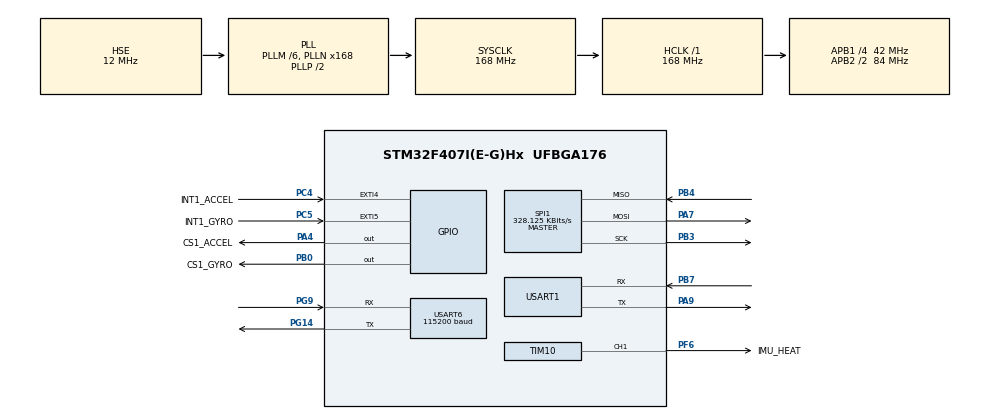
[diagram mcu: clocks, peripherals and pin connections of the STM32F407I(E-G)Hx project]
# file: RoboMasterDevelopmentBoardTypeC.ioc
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Dma.Request0=USART1_TX
Dma.USART1_TX.0.Direction=DMA_MEMORY_TO_PERIPH
Dma.USART1_TX.0.FIFOMode=DMA_FIFOMODE_DISABLE
Dma.USART1_TX.0.Instance=DMA2_Stream7
Dma.USART1_TX.0.MemDataAlignment=DMA_MDATAALIGN_BYTE
Dma.USART1_TX.0.MemInc=DMA_MINC_ENABLE
Dma.USART1_TX.0.Mode=DMA_NORMAL
Dma.USART1_TX.0.PeriphDataAlignment=DMA_PDATAALIGN_BYTE
Dma.USART1_TX.0.PeriphInc=DMA_PINC_DISABLE
Dma.USART1_TX.0.Priority=DMA_PRIORITY_MEDIUM
Mcu.Family=STM32F4
Mcu.Name=STM32F407I(E-G)Hx
Mcu.Package=UFBGA176
NVIC.DMA2_Stream7_IRQn=true\:6\:0\:true\:false\:true\:false\:true\:true
NVIC.PriorityGroup=NVIC_PRIORITYGROUP_4
NVIC.TIM5_IRQn=true\:0\:0\:false\:false\:false\:true\:false\:true
NVIC.TIM7_IRQn=true\:0\:0\:true\:false\:true\:false\:true\:true
NVIC.TimeBase=TIM7_IRQn
NVIC.TimeBaseIP=TIM7
NVIC.USART1_IRQn=true\:6\:0\:true\:false\:true\:true\:true\:true
PA13.Mode=Serial_Wire
PA13.Signal=SYS_JTMS-SWDIO
PA14.Mode=Serial_Wire
PA14.Signal=SYS_JTCK-SWCLK
PA4.GPIO_Label=CS1_ACCEL
PA4.GPIO_ModeDefaultOutputPP=GPIO_MODE_OUTPUT_PP
PA4.GPIO_PuPd=GPIO_PULLUP
PA4.GPIO_Speed=GPIO_SPEED_FREQ_HIGH
PA4.PinState=GPIO_PIN_SET
PA4.Signal=GPIO_Output
PA7.Mode=Full_Duplex_Master
PA7.Signal=SPI1_MOSI
PA9.Mode=Asynchronous
PA9.Signal=USART1_TX
PB0.GPIO_Label=CS1_GYRO
PB0.GPIO_PuPd=GPIO_PULLUP
PB0.GPIO_Speed=GPIO_SPEED_FREQ_HIGH
PB0.PinState=GPIO_PIN_SET
PB0.Signal=GPIO_Output
PB3.Mode=Full_Duplex_Master
PB3.Signal=SPI1_SCK
PB4.Mode=Full_Duplex_Master
PB4.Signal=SPI1_MISO
PB7.Mode=Asynchronous
PB7.Signal=USART1_RX
PC4.GPIO_Label=INT1_ACCEL
PC4.GPIO_ModeDefaultEXTI=GPIO_MODE_IT_FALLING
PC4.GPIO_PuPd=GPIO_PULLUP
PC4.Signal=GPXTI4
PC5.GPIO_Label=INT1_GYRO
PC5.GPIO_ModeDefaultEXTI=GPIO_MODE_IT_FALLING
PC5.GPIO_PuPd=GPIO_PULLUP
PC5.Signal=GPXTI5
PF6.GPIO_Label=IMU_HEAT
PF6.GPIO_PuPd=GPIO_PULLUP
PF6.GPIO_Speed=GPIO_SPEED_FREQ_HIGH
PF6.Signal=S_TIM10_CH1
PG14.Mode=Asynchronous
PG14.Signal=USART6_TX
PG9.Mode=Asynchronous
PG9.Signal=USART6_RX
PH0-OSC_IN.Mode=HSE-External-Oscillator
PH0-OSC_IN.Signal=RCC_OSC_IN
PH1-OSC_OUT.Mode=HSE-External-Oscillator
PH1-OSC_OUT.Signal=RCC_OSC_OUT
ProjectManager.HeapSize=0x2000
ProjectManager.StackSize=0x2000
ProjectManager.TargetToolchain=CMake
RCC.48MHZClocksFreq_Value=48000000
RCC.AHBFreq_Value=168000000
RCC.APB1CLKDivider=RCC_HCLK_DIV4
RCC.APB1Freq_Value=42000000
RCC.APB1TimFreq_Value=84000000
RCC.APB2CLKDivider=RCC_HCLK_DIV2
RCC.APB2Freq_Value=84000000
RCC.APB2TimFreq_Value=168000000
RCC.CortexFreq_Value=168000000
RCC.HCLKFreq_Value=168000000
RCC.HSE_VALUE=12000000
RCC.HSI_VALUE=16000000
RCC.LSE_VALUE=32768
RCC.PLLM=6
RCC.PLLN=168
RCC.PLLQ=7
RCC.PLLSourceVirtual=RCC_PLLSOURCE_HSE
RCC.SYSCLKFreq_VALUE=168000000
RCC.SYSCLKSource=RCC_SYSCLKSOURCE_PLLCLK
RCC.VCOOutputFreq_Value=336000000
SH.S_TIM10_CH1.0=TIM10_CH1,PWM Generation1 CH1
SPI1.BaudRatePrescaler=SPI_BAUDRATEPRESCALER_256
SPI1.CLKPhase=SPI_PHASE_2EDGE
SPI1.CLKPolarity=SPI_POLARITY_HIGH
SPI1.CalculateBaudRate=328.125 KBits/s
SPI1.Direction=SPI_DIRECTION_2LINES
SPI1.Mode=SPI_MODE_MASTER
SPI1.VirtualType=VM_MASTER
STMicroelectronics.X-CUBE-ALGOBUILD.1.4.0.LibraryCcDSPOoLibraryJjDSPOoLibrary=true
TIM10.Channel=TIM_CHANNEL_1
TIM10.Period=20000 - 1
TIM10.Prescaler=84 - 1
TIM5.Period=0xFFFFFFFF
TIM5.Prescaler=84 - 1
USART1.VirtualMode=VM_ASYNC
USART6.BaudRate=115200
USART6.Mode=MODE_TX
USART6.VirtualMode=VM_ASYNC
VP_STMicroelectronics.X-CUBE-ALGOBUILD_VS_DSPOoLibraryJjLibrary_1.4.0_1.4.0.Mode=DSPOoLibraryJjLibrary
VP_SYS_VS_tim7.Mode=TIM7
VP_TIM10_VS_ClockSourceINT.Mode=Enable_Timer
VP_TIM5_VS_ClockSourceINT.Mode=Internal
board=custom

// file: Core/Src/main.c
/* USER CODE BEGIN Header */
/**
  ******************************************************************************
  * @file           : main.c
  * @brief          : Main program body
  ******************************************************************************
  * @attention
  *
  * Copyright (c) 2025 STMicroelectronics.
  * All rights reserved.
  *
  * This software is licensed under terms that can be found in the LICENSE file
  * in the root directory of this software component.
  * If no LICENSE file comes with this software, it is provided AS-IS.
  *
  ******************************************************************************
  */
/* USER CODE END Header */
#include "main.h"
#include "dma.h"
#include "spi.h"
#include "tim.h"
#include "usart.h"
#include "gpio.h"

/* USER CODE BEGIN Includes */

#include "rmdev_test.h"

/* USER CODE END Includes */

void SystemClock_Config(void);

int main(void)
{

  /* MCU Configuration--------------------------------------------------------*/

  /* Reset of all peripherals, Initializes the Flash interface and the Systick. */
  HAL_Init();

  /* Configure the system clock */
  SystemClock_Config();

  /* Initialize all configured peripherals */
  MX_GPIO_Init();
  MX_DMA_Init();
  MX_TIM5_Init();
  MX_USART6_UART_Init();
  MX_SPI1_Init();
  MX_TIM10_Init();
  MX_USART1_UART_Init();
  /* USER CODE BEGIN 2 */

  LL_TIM_DisableCounter(TIM5);
  LL_TIM_SetCounter(TIM5, 0U);
  LL_TIM_ClearFlag_UPDATE(TIM5);
  LL_TIM_EnableIT_UPDATE(TIM5);
  LL_TIM_EnableCounter(TIM5);

  testEntry();

  /* USER CODE END 2 */

  /* Infinite loop */
  while (1)
  {

  }
}

void SystemClock_Config(void)
{
  RCC_OscInitTypeDef RCC_OscInitStruct = {0};
  RCC_ClkInitTypeDef RCC_ClkInitStruct = {0};

  /** Configure the main internal regulator output voltage
  */
  __HAL_RCC_PWR_CLK_ENABLE();
  __HAL_PWR_VOLTAGESCALING_CONFIG(PWR_REGULATOR_VOLTAGE_SCALE1);

  /** Initializes the RCC Oscillators according to the specified parameters
  * in the RCC_OscInitTypeDef structure.
  */
  RCC_OscInitStruct.OscillatorType = RCC_OSCILLATORTYPE_HSE;
  RCC_OscInitStruct.HSEState = RCC_HSE_ON;
  RCC_OscInitStruct.PLL.PLLState = RCC_PLL_ON;
  RCC_OscInitStruct.PLL.PLLSource = RCC_PLLSOURCE_HSE;
  RCC_OscInitStruct.PLL.PLLM = 6;
  RCC_OscInitStruct.PLL.PLLN = 168;
  RCC_OscInitStruct.PLL.PLLP = RCC_PLLP_DIV2;
  RCC_OscInitStruct.PLL.PLLQ = 7;
  if (HAL_RCC_OscConfig(&RCC_OscInitStruct) != HAL_OK)
  {
    Error_Handler();
  }

  /** Initializes the CPU, AHB and APB buses clocks
  */
  RCC_ClkInitStruct.ClockType = RCC_CLOCKTYPE_HCLK|RCC_CLOCKTYPE_SYSCLK
                              |RCC_CLOCKTYPE_PCLK1|RCC_CLOCKTYPE_PCLK2;
  RCC_ClkInitStruct.SYSCLKSource = RCC_SYSCLKSOURCE_PLLCLK;
  RCC_ClkInitStruct.AHBCLKDivider = RCC_SYSCLK_DIV1;
  RCC_ClkInitStruct.APB1CLKDivider = RCC_HCLK_DIV4;
  RCC_ClkInitStruct.APB2CLKDivider = RCC_HCLK_DIV2;

  if (HAL_RCC_ClockConfig(&RCC_ClkInitStruct, FLASH_LATENCY_5) != HAL_OK)
  {
    Error_Handler();
  }
}

void HAL_TIM_PeriodElapsedCallback(TIM_HandleTypeDef *htim)
{
  if (htim->Instance == TIM7)
  {
    HAL_IncTick();
  }
}

void Error_Handler(void)
{
  __disable_irq();
  while (1)
  {
  }
}
